# bao1x register map
Vendor: baochip; File version: 1.0
Registers are 32-bit, read-write, reset 0x0 unless marked. A register's access mark holds for its fields unless they carry their own. Offsets are from the block's base; [hi:lo] are bit positions; {n}, {i} and the like mark numbered series; <NAME> marks a mode.

## UDMA_ADC
Base 0x50114000
0x00 REG_RX_SADDR — See `udma_adc_ts_reg_if.sv <https://github.com/baochip/baochip-1x/blob/main/rtl/ modules/ifsub/rtl/udma_adc_ts_reg_if.sv>`__
  [11:0] r_rx_startaddr
0x04 REG_RX_SIZE — See `udma_adc_ts_reg_if.sv <https://github.com/baochip/baochip-1x/blob/main/rtl/ modules/ifsub/rtl/udma_adc_ts_reg_if.sv>`__
  [15:0] r_rx_size
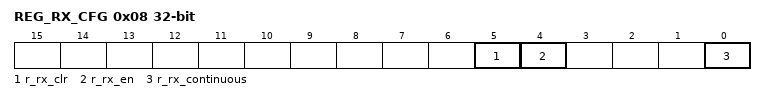
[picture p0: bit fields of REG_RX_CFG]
0x08 REG_RX_CFG — See `udma_adc_ts_reg_if.sv <https://github.com/baochip/baochip-1x/blob/main/rtl/ modules/ifsub/rtl/udma_adc_ts_reg_if.sv>`__
  [5] r_rx_clr, [4] r_rx_en, [0] r_rx_continuous
0x10 REG_CR_ADC — See `udma_adc_ts_reg_if.sv <https://github.com/baochip/baochip-1x/blob/main/rtl/ modules/ifsub/rtl/udma_adc_ts_reg_if.sv>`__
  [27:0] cr_adc

## BIO_FIFO0
Base 0x50129000
Same registers: BIO_FIFO1 0x5012A000, BIO_FIFO2 0x5012B000, BIO_FIFO3 0x5012C000
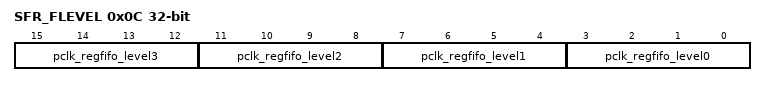
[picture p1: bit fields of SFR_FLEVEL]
0x0C SFR_FLEVEL — See `bio_bdma.sv#L492 <https://github.com/baochip/baochip-1x/blob/main/rtl/modul es/bio_bdma/rtl/bio_bdma.sv#L492>`__ (line numbers are approximate)
  [4n+3:4n] pclk_regfifo_level{n} (n=0..3) — pclk_regfifo_level[{n}] read only status register
0x10 SFR_TXF0 — See `bio_bdma.sv#L493 <https://github.com/baochip/baochip-1x/blob/main/rtl/modul es/bio_bdma/rtl/bio_bdma.sv#L493>`__ (line numbers are approximate)
  [31:0] fdin — fdin read/write control register
0x20 SFR_RXF0 — See `bio_bdma.sv#L497 <https://github.com/baochip/baochip-1x/blob/main/rtl/modul es/bio_bdma/rtl/bio_bdma.sv#L497>`__ (line numbers are approximate)
  [31:0] fdout — fdout read only status register
0x38 SFR_EVENT_SET — See `bio_bdma.sv#L504 <https://github.com/baochip/baochip-1x/blob/main/rtl/modul es/bio_bdma/rtl/bio_bdma.sv#L504>`__ (line numbers are approximate)
  [23:0] sfr_event_set — sfr_event_set read/write control register
0x3C SFR_EVENT_CLR — See `bio_bdma.sv#L505 <https://github.com/baochip/baochip-1x/blob/main/rtl/modul es/bio_bdma/rtl/bio_bdma.sv#L505>`__ (line numbers are approximate)
  [23:0] sfr_event_clr — sfr_event_clr read/write control register
0x40 SFR_EVENT_STATUS — See `bio_bdma.sv#L506 <https://github.com/baochip/baochip-1x/blob/main/rtl/modul es/bio_bdma/rtl/bio_bdma.sv#L506>`__ (line numbers are approximate)
  [31:0] sfr_event_status — sfr_event_status read only status register

## D11CTIME
Base 0xE0000000
0x00 CONTROL reset 0x61A80
  [31:0] count — Number of ACLK ticks before creating a heart beat
0x04 HEARTBEAT
  [0] beat — Set to `1` at the next `count` interval rollover since `clear` was set.

## SUSRES
Base 0xE0001000
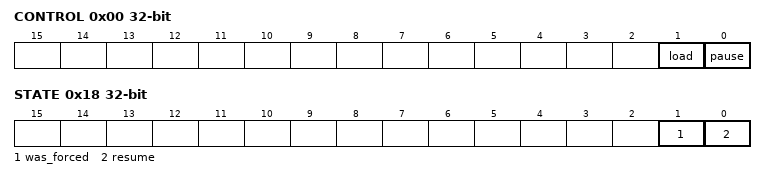
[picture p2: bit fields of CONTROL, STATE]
0x00 CONTROL
  [1] load — If paused, write a `1` to this bit to load a resume value to the timer. If not paused, this bit is ignored.
  [0] pause — Write a `1` to this field to request a pause to counting, 0 for free-run. Count pauses on the next tick quanta.
0x04 RESUME_TIME1 — Bits 32-63 of `SUSRES_RESUME_TIME`. Elapsed time to load. Loaded upon writing `1` to the load bit in the control register. This will immediately affect the msleep extension.
  [31:0] resume_time
0x08 RESUME_TIME0 — Bits 0-31 of `SUSRES_RESUME_TIME`.
  [31:0] resume_time
0x0C TIME1 — Bits 32-63 of `SUSRES_TIME`. Cycle-accurate mirror copy of time in systicks, from the TickTimer
  [31:0] time
0x10 TIME0 — Bits 0-31 of `SUSRES_TIME`.
  [31:0] time
0x14 STATUS
  [0] paused — When set, indicates that the counter has been paused
0x18 STATE
  [1] was_forced — Used by the bootloader to indicate to the kernel if the current resume was from a forced suspend (e.g. a timeout happened and a server may be unclean.
  [0] resume — Used to transfer the resume state information from the loader to Xous. If set, indicates we are on the resume half of a suspend/resume.
0x1C INTERRUPT
  [0] interrupt — Writing this causes an interrupt to fire. Used by Xous to initiate suspend/resume from an interrupt context.
0x20 EV_STATUS — This register contains the current raw level of the soft_int event trigger. Writes to this register have no effect.
  [0] soft_int — Level of the ``soft_int`` event
0x24 EV_PENDING — When a soft_int event occurs, the corresponding bit will be set in this register. To clear the Event, set the corresponding bit in this register.
  [0] soft_int — `1` if a `soft_int` event occurred. This Event is triggered on a **falling** edge.
0x28 EV_ENABLE — This register enables the corresponding soft_int events. Write a ``0`` to this register to disable individual events.
  [0] soft_int — Write a ``1`` to enable the ``soft_int`` Event
